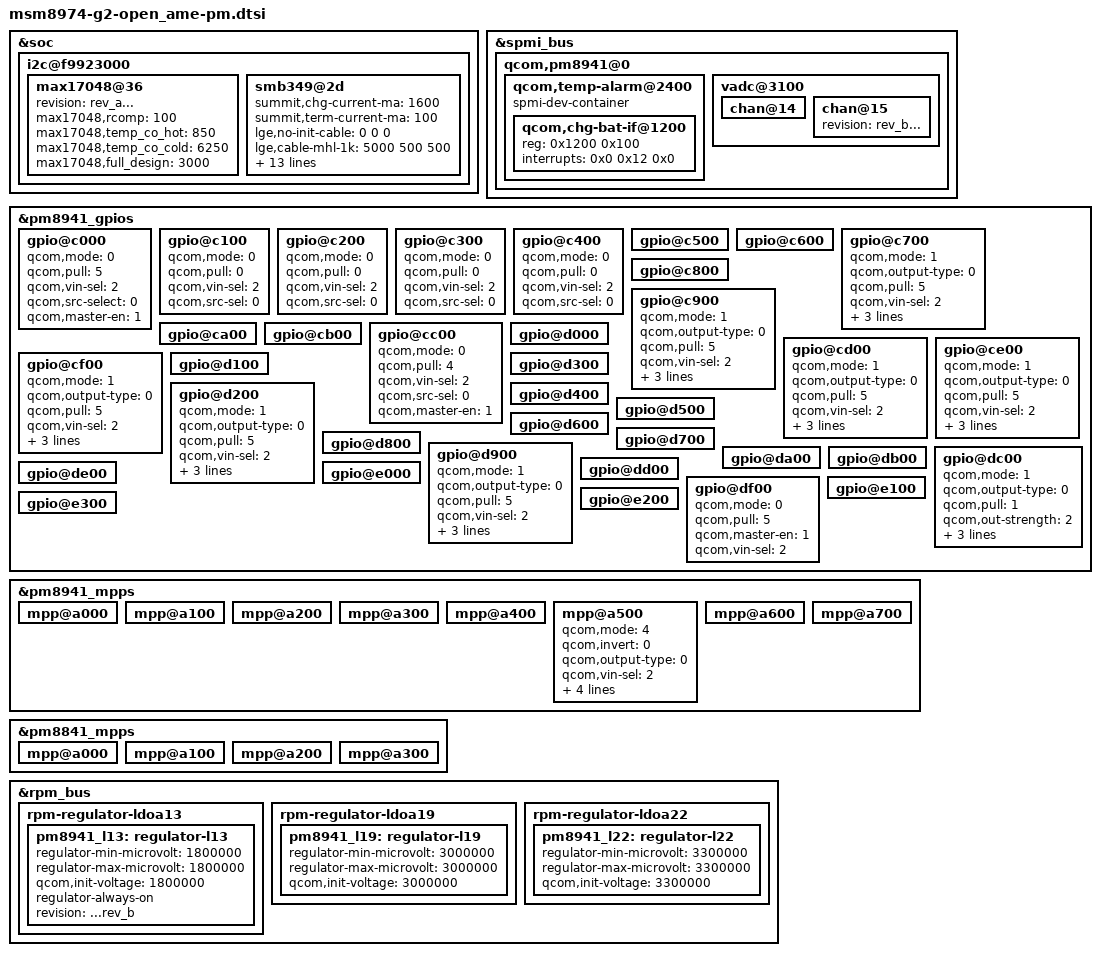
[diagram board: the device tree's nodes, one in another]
/* Copyright (c) 2012, Code Aurora Forum. All rights reserved.
 *
 * This program is free software; you can redistribute it and/or modify
* it under the terms of the GNU General Public License version 2 and
* only version 2 as published by the Free Software Foundation.
*
* This program is distributed in the hope that it will be useful,
* but WITHOUT ANY WARRANTY; without even the implied warranty of
* MERCHANTABILITY or FITNESS FOR A PARTICULAR PURPOSE.  See the
* GNU General Public License for more details.
*/

&soc {
	i2c@f9923000 {
		max17048@36 {
			status =  "ok";
			revision = "rev_a...";
			max17048,rcomp = <100>;
			max17048,temp_co_hot = <850>;
			max17048,temp_co_cold = <6250>;
			max17048,full_design = <3000>;
		};

		smb349@2d {
			status = "ok";
			summit,chg-current-ma = <1600>;
			summit,term-current-ma = <100>;

			lge,no-init-cable = <0 0 0>;
			lge,cable-mhl-1k = <5000 500 500>;
			lge,cable-u-28p7k = <5500 1600 500>;
			lge,cable-28p7k = <6000 1600 500>;
			lge,cable-56k = <200000 1500 1500>;
			lge,cable-100k = <239000 1600 500>;
			lge,cable-130k = <340000 1500 1500>;
			lge,cable-180k = <400000 1600 500>;
			lge,cable-200k = <410000 1600 500>;
			lge,cable-220k = <485000 1600 500>;
			lge,cable-270k = <560000 1600 500>;
			lge,cable-330k = <735000 1600 500>;
			lge,cable-620k = <955000 1600 500>;
			lge,cable-910k = <1140000 1500 1500>;
			lge,cable-none = <1900000 1600  500>;
		};
	};
};

&spmi_bus {
	qcom,pm8941@0 {
		qcom,temp-alarm@2400 {
			spmi-dev-container;
			#address-cells = <1>;
			#size-cells = <1>;
			qcom,chg-bat-if@1200 {
				status = "ok";
				reg = <0x1200 0x100>;
				interrupts =	<0x0 0x12 0x0>;
				interrupt-names = "batt-pres";
			};
		};

		vadc@3100 {
			chan@14 {
				status = "ok";
			};

			chan@15 {
				status = "ok";
				revision = "rev_b...";
			};
		};

	};
};

&pm8941_gpios {
	gpio@c000 { /* GPIO 1 */
		status = "ok";
		qcom,mode = <0>;
		qcom,pull = <5>;
		qcom,vin-sel = <2>;
		qcom,src-select = <0>;
		qcom,master-en = <1>;
	};

	gpio@c100 { /* GPIO 2 */
		qcom,mode = <0>;
		qcom,pull = <0>;
		qcom,vin-sel = <2>;
		qcom,src-sel = <0>;
	};

	gpio@c200 { /* GPIO 3 */
		qcom,mode = <0>;
		qcom,pull = <0>;
		qcom,vin-sel = <2>;
		qcom,src-sel = <0>;
	};

	gpio@c300 { /* GPIO 4 */
		qcom,mode = <0>;
		qcom,pull = <0>;
		qcom,vin-sel = <2>;
		qcom,src-sel = <0>;
	};

	gpio@c400 { /* GPIO 5 */
		qcom,mode = <0>;
		qcom,pull = <0>;
		qcom,vin-sel = <2>;
		qcom,src-sel = <0>;
	};

	gpio@c500 { /* GPIO 6 */
	};

	gpio@c600 { /* GPIO 7 */
	};

	gpio@c700 { /* GPIO 8 */
		status = "ok";
		qcom,mode = <1>;		/* QPNP_PIN_MODE_DIG_OUT */
		qcom,output-type = <0>;		/* QPNP_PIN_OUT_BUF_CMOS */
		qcom,pull = <5>;		/* QPNP_PIN_PULL_NO */
		qcom,vin-sel = <2>;		/* QPNP_PIN_VIN2 */
		qcom,out-strength = <2>;	/* QPNP_PIN_OUT_STRENGTH_MED */
		qcom,src-select = <0>;		/* QPNP_PIN_SEL_FUNC_CONSTANT */
		qcom,master-en = <1>;
	};

	gpio@c800 { /* GPIO 9 */
	};

	gpio@c900 { /* GPIO 10 */
		status = "ok";
		qcom,mode = <1>;		/* QPNP_PIN_MODE_DIG_OUT */
		qcom,output-type = <0>;		/* QPNP_PIN_OUT_BUF_CMOS */
		qcom,pull = <5>;		/* QPNP_PIN_PULL_NO */
		qcom,vin-sel = <2>;		/* QPNP_PIN_VIN2 */
		qcom,out-strength = <2>;	/* QPNP_PIN_OUT_STRENGTH_MED */
		qcom,src-select = <0>;		/* QPNP_PIN_SEL_FUNC_CONSTANT */
		qcom,master-en = <1>;
	};

	gpio@ca00 { /* GPIO 11 */
	};

	gpio@cb00 { /* GPIO 12 */
	};

	gpio@cc00 { /* GPIO 13 */ /* LGE_CHANGE, SlimPort Cable Det IRQ */
		status = "ok";
		qcom,mode = <0>;		/* QPNP_PIN_MODE_DIG_IN */
		qcom,pull = <4>;		/* QPNP_PIN_PULL_DN */
		qcom,vin-sel = <2>;		/* QPNP_PIN_VIN2 */
		qcom,src-sel = <0>;		/* QPNP_PIN_SEL_FUNC_CONSTANT */
		qcom,master-en = <1>;
	};

	gpio@cd00 { /* GPIO 14 */ /* LGE_CHANGE, SlimPort PWR Ctl Pin Setting */
		status = "ok";
		qcom,mode = <1>;		/* QPNP_PIN_MODE_DIG_OUT */
		qcom,output-type = <0>;		/* QPNP_PIN_OUT_BUF_CMOS */
		qcom,pull = <5>;		/* QPNP_PIN_PULL_NO */
		qcom,vin-sel = <2>;		/* QPNP_PIN_VIN2 */
		qcom,out-strength = <2>;	/* QPNP_PIN_OUT_STRENGTH_MED */
		qcom,src-sel = <0>;		/* QPNP_PIN_SEL_FUNC_CONSTANT */
		qcom,master-en = <1>;
	};

	gpio@ce00 { /* GPIO 15 */
		qcom,mode = <1>;
		qcom,output-type = <0>;
		qcom,pull = <5>;
		qcom,vin-sel = <2>;
		qcom,out-strength = <3>;
		qcom,src-sel = <2>;
		qcom,master-en = <1>;
	};

	gpio@cf00 { /* GPIO 16 */ /* LGE_CHANGE, [BT][younghyun.kwon@lge.com], 2013-02-26, BT Sleep clock(32KHz) configuration*/
		qcom,mode = <1>;
		qcom,output-type = <0>;
		qcom,pull = <5>;
		qcom,vin-sel = <2>;
		qcom,out-strength = <3>;
		qcom,src-sel = <3>;
		qcom,master-en = <1>;
	};

	gpio@d000 { /* GPIO 17 */
	};

	gpio@d100 { /* GPIO 18 */
	};

	gpio@d200 { /* GPIO 19 */
		qcom,mode = <1>;		/* QPNP_PIN_MODE_DIG_OUT */
		qcom,output-type = <0>;		/* QPNP_PIN_OUT_BUF_CMOS */
		qcom,pull = <5>;		/* QPNP_PIN_PULL_NO */
		qcom,vin-sel = <2>;		/* QPNP_PIN_VIN2 */
		qcom,out-strength = <2>;	/* QPNP_PIN_OUT_STRENGTH_MED */
		qcom,src-sel = <0>;		/* QPNP_PIN_SEL_FUNC_CONSTANT */
		qcom,master-en = <1>;
	};

	gpio@d300 { /* GPIO 20 */
	};

	gpio@d400 { /* GPIO 21 */
	};

	gpio@d500 { /* GPIO 22 */
	};

	gpio@d600 { /* GPIO 23 */
	};

	gpio@d700 { /* GPIO 24 */
	};

	gpio@d800 { /* GPIO 25 */
	};

	gpio@d900 { /* GPIO 26 */
		status = "ok";
		qcom,mode = <1>;		/* QPNP_PIN_MODE_DIG_OUT */
		qcom,output-type = <0>;		/* QPNP_PIN_OUT_BUF_CMOS */
		qcom,pull = <5>;		/* QPNP_PIN_PULL_NO */
		qcom,vin-sel = <2>;		/* QPNP_PIN_VIN2 */
		qcom,out-strength = <2>;	/* QPNP_PIN_OUT_STRENGTH_MED */
		qcom,src-select = <0>;		/* QPNP_PIN_SEL_FUNC_CONSTANT */
		qcom,master-en = <1>;
	};

	gpio@da00 { /* GPIO 27 */
	};

	gpio@db00 { /* GPIO 28 */
	};

	gpio@dc00 { /* GPIO 29 */
		status = "ok";
		qcom,mode = <1>;
		qcom,output-type = <0>;
		qcom,pull = <1>; /* set to default pull */
		qcom,out-strength = <2>;
		com,vin-sel = <2>; /* select 1.8 V source */
		qcom,src-select = <0>;      /* QPNP_PIN_SEL_FUNC_CONSTANT */
		qcom,master-en = <1>;
	};

	gpio@dd00 { /* GPIO 30 */
	};

	gpio@de00 { /* GPIO 31 */
	};

	gpio@df00 { /* GPIO 32 */
		status = "ok";
		qcom,mode = <0>;		/* QPNP_PIN_MODE_DIG_IN */
		qcom,pull = <5>;		/* QPNP_PIN_PULL_NO */
		qcom,master-en = <1>;		/* Enable Module */
		qcom,vin-sel = <2>;		/* Select 1.8V Source */
	};

	gpio@e000 { /* GPIO 33 */
	};

	gpio@e100 { /* GPIO 34 */
	};

	gpio@e200 { /* GPIO 35 */
	};

	gpio@e300 { /* GPIO 36 */
	};
};

&pm8941_mpps {

	mpp@a000 { /* MPP 1 */
	};

	mpp@a100 { /* MPP 2 */
	};

	mpp@a200 { /* MPP 3 */
	};

	mpp@a300 { /* MPP 4 */
	};

	mpp@a400 { /* MPP 5 */
		status = "ok";
	};

	mpp@a500 { /* MPP 6 */
		status = "ok";
		qcom,mode = <4>; /* QPNP_PIN_MODE_AIN */
		qcom,invert = <0>; /*no invert*/
		qcom,output-type = <0>; /* CMOS */
		qcom,vin-sel = <2>; /* PM8941_S3 1.8V > 1.6V */
		qcom,src-sel = <0>; /* CONSTANT */
		qcom,ain-route = <1>;
		qcom,master-en = <1>;
		revision = "rev_b...";
	};

	mpp@a600 { /* MPP 7 */
	};

	mpp@a700 { /* MPP 8 */
	};
};

&pm8841_mpps {

	mpp@a000 { /* MPP 1 */
	};

	mpp@a100 { /* MPP 2 */
	};

	mpp@a200 { /* MPP 3 */
	};

	mpp@a300 { /* MPP 4 */
	};
};

&rpm_bus {
    rpm-regulator-ldoa13 {
		status = "okay";
		pm8941_l13: regulator-l13 {
			regulator-min-microvolt = <1800000>;
			regulator-max-microvolt = <1800000>;
			qcom,init-voltage = <1800000>;
			regulator-always-on;
			revision = "...rev_b";
			status = "okay";
		};
	};

	rpm-regulator-ldoa19 {
		pm8941_l19: regulator-l19 {
			regulator-min-microvolt = <3000000>;
			regulator-max-microvolt = <3000000>;
			qcom,init-voltage = <3000000>;
		};
	};
	rpm-regulator-ldoa22 {
		pm8941_l22: regulator-l22 {
			regulator-min-microvolt = <3300000>;
			regulator-max-microvolt = <3300000>;
			qcom,init-voltage = <3300000>;
		};
	};
};
